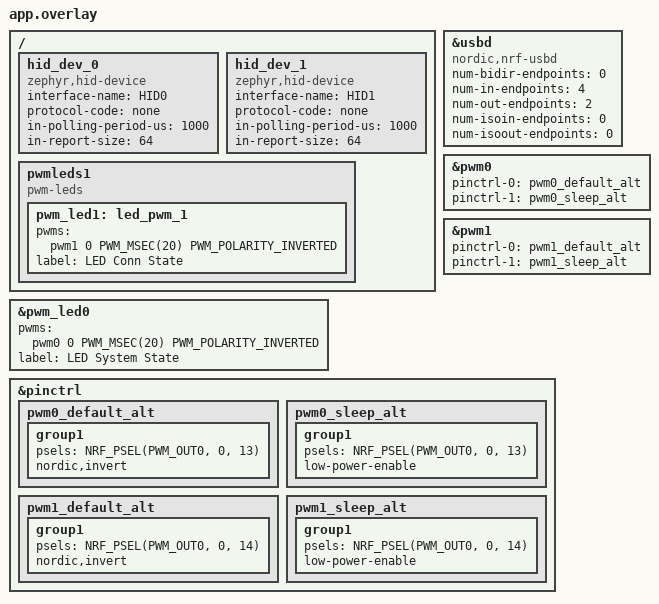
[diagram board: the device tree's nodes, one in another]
/ {
	/* Configure DTS nodes used for USB next HID support. */
	hid_dev_0: hid_dev_0 {
		compatible = "zephyr,hid-device";
		interface-name = "HID0";
		protocol-code = "none";
		in-polling-period-us = <1000>;
		in-report-size = <64>;
	};
	hid_dev_1: hid_dev_1 {
		compatible = "zephyr,hid-device";
		interface-name = "HID1";
		protocol-code = "none";
		in-polling-period-us = <1000>;
		in-report-size = <64>;
	};

	pwmleds1 {
		compatible = "pwm-leds";
		status = "okay";

		pwm_led1: led_pwm_1 {
			status = "okay";
			pwms = <&pwm1 0 PWM_MSEC(20) PWM_POLARITY_INVERTED>;
			label = "LED Conn State";
		};
	};
};

&usbd {
	compatible = "nordic,nrf-usbd";
	status = "okay";
	num-bidir-endpoints = <0>;
	num-in-endpoints = <4>;
	num-out-endpoints = <2>;
	num-isoin-endpoints = <0>;
	num-isoout-endpoints = <0>;
};

&pwm0 {
	status = "okay";
	pinctrl-0 = <&pwm0_default_alt>;
	pinctrl-1 = <&pwm0_sleep_alt>;
	pinctrl-names = "default", "sleep";
};

&pwm1 {
	status = "okay";
	pinctrl-0 = <&pwm1_default_alt>;
	pinctrl-1 = <&pwm1_sleep_alt>;
	pinctrl-names = "default", "sleep";
};

&pwm_led0 {
	status = "okay";
	pwms = <&pwm0 0 PWM_MSEC(20) PWM_POLARITY_INVERTED>;
	label = "LED System State";
};

&pinctrl {
	pwm0_default_alt: pwm0_default_alt {
		group1 {
			psels = <NRF_PSEL(PWM_OUT0, 0, 13)>;
			nordic,invert;
		};
	};

	pwm0_sleep_alt: pwm0_sleep_alt {
		group1 {
			psels = <NRF_PSEL(PWM_OUT0, 0, 13)>;
			low-power-enable;
		};
	};

	pwm1_default_alt: pwm1_default_alt {
		group1 {
			psels = <NRF_PSEL(PWM_OUT0, 0, 14)>;
			nordic,invert;
		};
	};

	pwm1_sleep_alt: pwm1_sleep_alt {
		group1 {
			psels = <NRF_PSEL(PWM_OUT0, 0, 14)>;
			low-power-enable;
		};
	};

};
